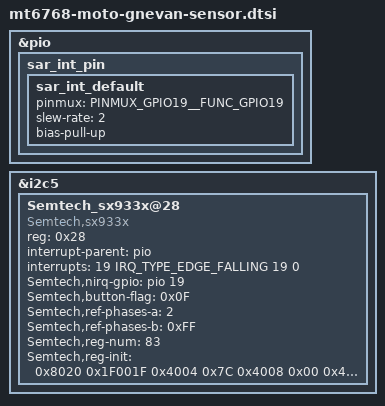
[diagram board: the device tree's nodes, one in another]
&pio {
    sar_int_pin {
        sar_int_default: sar_int_default {
            /* active state */
            pinmux = <PINMUX_GPIO19__FUNC_GPIO19>;
            slew-rate = <2>;
            bias-pull-up;
        };
    };
};


&i2c5{
	Semtech_sx933x@28 {
		compatible = "Semtech,sx933x";
		reg = <0x28>;
		interrupt-parent = <&pio>;
		interrupts = <19 IRQ_TYPE_EDGE_FALLING 19 0>;
		Semtech,nirq-gpio = <&pio 19 0x00>;
		/*use PH3/4 as the reference sensor
		set it to 0xff if the ref-phases-x is not used*/
		Semtech,button-flag = <0x0F>;
		Semtech,ref-phases-a = <2>;
		Semtech,ref-phases-b = <0xFF>;
		Semtech,reg-num = <83>;
		Semtech,reg-init = <
		0x8020 0x1F001F
		0x4004 0x7C
		0x4008 0x00
		0x4054 0x400
		0x4280 0xF
		0x42C0 0x8000000
		0x42C4 0x3F
		0x800C 0x00
		0x8010 0x00
		0x8014 0x00
		0x8018 0x00
		0x801C 0x31
		0x8024 0x10000A6E
		0x8028 0x3FFE82D8
		0x802C 0x10000A6E
		0x8030 0x3FF78260
		0x8034 0x10000A6E
		0x8038 0x2FFF835D
		0x803C 0x10000A76
		0x8040 0x3DFF8267
		0x8044 0x10000A76
		0x8048 0x3FBF82C6
		0x804C 0x88E
		0x8050 0x80001EE6
		0x8054 0x10323600
		0x8058 0x20630030
		0x805C 0x5300
		0x8060 0x00
		0x8064 0x8E0000
		0x8068 0x00
		0x806C 0x00
		0x8070 0x10000
		0x8074 0x10322305
		0x8078 0x20630030
		0x807C 0x5300
		0x8080 0x00
		0x8084 0x3A0000
		0x8088 0x00
		0x808C 0x200020
		0x8090 0x10022805
		0x8094 0x10321B05
		0x8098 0x20630030
		0x809C 0x10005310
		0x80A0 0x00
		0x80A4 0x00
		0x80A8 0x00
		0x80AC 0x00
		0x80B0 0x00
		0x80B4 0x10323305
		0x80B8 0x20630030
		0x80BC 0x5300
		0x80C0 0x00
		0x80C4 0x8D0000
		0x80C8 0x00
		0x80CC 0x00
		0x80D0 0x00
		0x80D4 0x1652FF05
		0x80D8 0x20630031
		0x80DC 0x7F805300
		0x80E0 0x00
		0x80E4 0x00
		0x80E8 0x00
		0x80EC 0x00
		0x80F0 0x00
		0x80F4 0x10162800
		0x80F8 0x20400031
		0x80FC 0x54AC5300
		0x8100 0x00
		0x8104 0x00
		0x8108 0x00
		0x810C 0x00
		0x8110 0x00
		0x8124 0x400000C
		0x8128 0x400000C
		0x812C 0x00
		0x8130 0x00
		0x8134 0x00
		0x8138 0x00
		0x813C 0x00
		0x8140 0x00
		0x8144 0x00
		0x8148 0x00
		0x814C 0x00
		0x81A4 0x1D40000>;
	};
};
